# RA register map
Vendor: Renesas; Series: All Chips; File version: x.xx
Registers are 32-bit, read-write, reset 0x0 unless marked. A register's access mark holds for its fields unless they carry their own. Offsets are from the block's base; [hi:lo] are bit positions; 'fields as' and 'values as' point back to an identical list.

## R_MSTP — System-Module Stop
Base 0x40047000
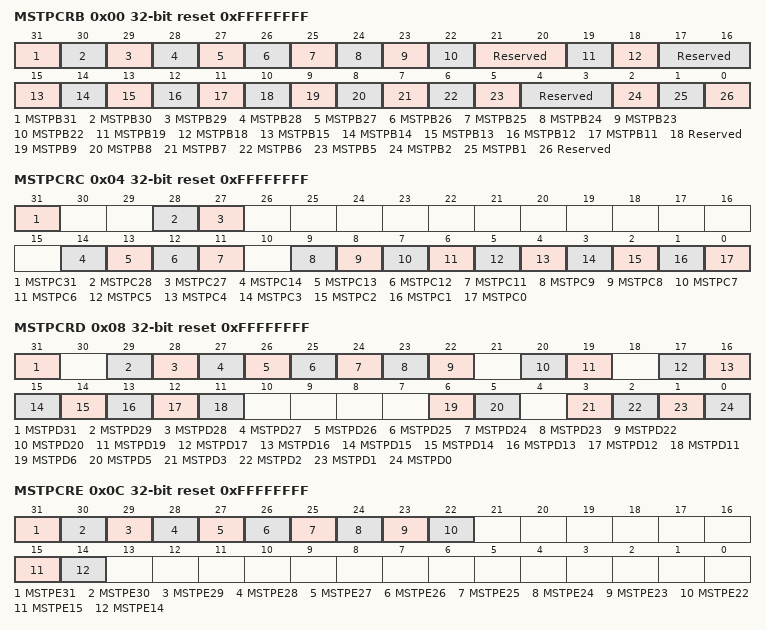
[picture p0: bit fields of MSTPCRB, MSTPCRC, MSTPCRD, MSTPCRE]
0x00 MSTPCRB reset 0xFFFFFFFF — Module Stop Control Register B
  [31] MSTPB31 — Serial Communication Interface 0 Module Stop
    0=Cancel the module-stop state; 1=Enter the module-stop state
  [30] MSTPB30 — Serial Communication Interface 1 Module Stop
    values as MSTPB31
  [29] MSTPB29 — Serial Communication Interface 2 Module Stop
    values as MSTPB31
  [28] MSTPB28 — Serial Communication Interface 3 Module Stop
    values as MSTPB31
  [27] MSTPB27 — Serial Communication Interface 4 Module Stop
    values as MSTPB31
  [26] MSTPB26 — Serial Communication Interface 5 Module Stop
    values as MSTPB31
  [25] MSTPB25 — Serial Communication Interface 6 Module Stop
    values as MSTPB31
  [24] MSTPB24 — Serial Communication Interface 7 Module Stop
    values as MSTPB31
  [23] MSTPB23 — Serial Communication Interface 8 Module Stop
    values as MSTPB31
  [22] MSTPB22 — Serial Communication Interface 9 Module Stop
    values as MSTPB31
  [21:20] Reserved — These bits are read as 11. The write value should be 11.
  [19] MSTPB19 — Serial Peripheral Interface 0 Module Stop
    values as MSTPB31
  [18] MSTPB18 — Serial Peripheral Interface Module Stop
    values as MSTPB31
  [17:16] Reserved — These bits are read as 11. The write value should be 11.
  [15] MSTPB15 — ETHERC0 and EDMAC0 Module Stop
    values as MSTPB31
  [14] MSTPB14 — ETHERC1 and EDMAC1 Module Stop
    values as MSTPB31
  [13] MSTPB13 — EPTPC and PTPEDMAC Module Stop
    values as MSTPB31
  [12] MSTPB12 — Universal Serial Bus 2.0 HS Interface Module Stop
    values as MSTPB31
  [11] MSTPB11 — Universal Serial Bus 2.0 FS Interface Module Stop
    values as MSTPB31
  [10] Reserved — This bit is read as 1. The write value should be 1.
  [9] MSTPB9 — IIC/I3C Bus Interface 0 Module Stop
    values as MSTPB31
  [8] MSTPB8 — I2C Bus Interface 1 Module Stop
    values as MSTPB31
  [7] MSTPB7 — I2C Bus Interface 2 Module Stop
    values as MSTPB31
  [6] MSTPB6 — Queued Serial Peripheral Interface Module Stop
    values as MSTPB31
  [5] MSTPB5 — IrDA Module Stop
    values as MSTPB31
  [4:3] Reserved — These bits are read as 11. The write value should be 11.
  [2] MSTPB2 — RCAN0 Module Stop
    values as MSTPB31
  [1] MSTPB1 — RCAN1 Module Stop
    values as MSTPB31
  [0] Reserved — This bit is read as 1. The write value should be 1.
0x04 MSTPCRC reset 0xFFFFFFFF — Module Stop Control Register C
  [all] fields
    values as MSTPCRB.MSTPB31
  [31] MSTPC31 — AES Module Stop
  [28] MSTPC28 — Random Number Generator Module Stop
  [27] MSTPC27 — CANFD Module Stop
  [14] MSTPC14 — Event Link Controller Module Stop
  [13] MSTPC13 — Data Operation Circuit Module Stop
  [12] MSTPC12 — Secure Digital Host IF/ Multi Media Card 0 Module Stop
  [11] MSTPC11 — Secure Digital Host IF/ Multi Media Card 1 Module Stop
  [9] MSTPC9 — Sampling Rate Converter Module Stop
  [8] MSTPC8 — Synchronous Serial Interface 0 Module Stop
  [7] MSTPC7 — Synchronous Serial Interface 1 Module Stop
  [6] MSTPC6 — 2DG engine Module Stop
  [5] MSTPC5 — JPEG codec engine Module Stop
  [4] MSTPC4 — Segment LCD Controller Module Stop
  [3] MSTPC3 — Capacitive Touch Sensing Unit Module Stop
  [2] MSTPC2 — Parallel Data Capture Module Stop
  [1] MSTPC1 — CRC Calculator Module Stop
  [0] MSTPC0 — CAC Module Stop
0x08 MSTPCRD reset 0xFFFFFFFF — Module Stop Control Register D
  [all] fields
    values as MSTPCRB.MSTPB31
  [31] MSTPD31 — Operational Amplifier Module Stop
  [29] MSTPD29 — Comparator-LP Module Stop
  [28] MSTPD28 — ACMPHS0 Module Stop
  [27] MSTPD27 — ACMPHS1 Module Stop
  [26] MSTPD26 — ACMPHS2 Module Stop
  [25] MSTPD25 — ACMPHS3 Module Stop
  [24] MSTPD24 — ACMPHS4 Module Stop
  [23] MSTPD23 — ACMPHS5 Module Stop
  [22] MSTPD22 — Temperature Sensor Module Stop
  [20] MSTPD20 — 12-bit D/A Converter Module Stop
  [19] MSTPD19 — 8-Bit D/A Converter Module Stop
  [17] MSTPD17 — 24-bit Sigma-Delta A/DConverter Module Stop
  [16] MSTPD16 — 16-Bit A/D Converter Module Stop
  [15] MSTPD15 — 12-Bit A/D Converter 1 Module Stop
  [14] MSTPD14 — POEG Module Stop
  [13] MSTPD13 — Port Output Enable for GPT 1 Module Stop
  [12] MSTPD12 — Port Output Enable for GPT 2 Module Stop
  [11] MSTPD11 — Port Output Enable for GPT 3 Module Stop
  [6] MSTPD6 — GPT Higher Module Stop
  [5] MSTPD5 — GPT Lower Module Stop
  [3] MSTPD3 — AGT0 Module StopNote: AGT0 is in the module stop state when the count source is either of PCLKB, PCLKB/2 or PCLKB/8. In case the count source is sub-clock or LOCO, this bit should be set to 1 except when accessing the registers of AGT0.
  [2] MSTPD2 — AGT1 Module StopNote: AGT1 is in the module stop state when the count source is either of PCLKB, PCLKB/2 or PCLKB/8. In case the count source is sub-clock or LOCO, this bit should be set to 1 except when accessing the registers of AGT1.
  [1] MSTPD1 — Low Power Asynchronous General Purpose Timer 2 Module Stop
  [0] MSTPD0 — Low Power Asynchronous General Purpose Timer 3 Module Stop
0x0C MSTPCRE reset 0xFFFFFFFF — Module Stop Control Register E
  [all] fields
    values as MSTPCRB.MSTPB31
  [31] MSTPE31 — GPT0 Module Stop
  [30] MSTPE30 — GPT1 Module Stop
  [29] MSTPE29 — GPT2 Module Stop
  [28] MSTPE28 — GPT3 Module Stop
  [27] MSTPE27 — GPT4 Module Stop
  [26] MSTPE26 — GPT5 Module Stop
  [25] MSTPE25 — GPT6 Module Stop
  [24] MSTPE24 — GPT7 Module Stop
  [23] MSTPE23 — GPT8 Module Stop
  [22] MSTPE22 — GPT9 Module Stop
  [15] MSTPE15 — Low Power Asynchronous General Purpose Timer 4 Module Stop
  [14] MSTPE14 — Low Power Asynchronous General Purpose Timer 5 Module Stop
